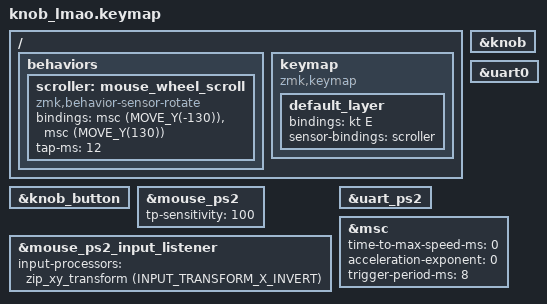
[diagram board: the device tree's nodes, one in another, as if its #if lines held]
#include <behaviors.dtsi>
#include <dt-bindings/zmk/keys.h>
#include <dt-bindings/zmk/pointing.h>
#include <dt-bindings/zmk/mouse.h>
#include <dt-bindings/zmk/input_transform.h>

&knob {
    status = "okay";
};
&knob_button {
    status = "okay";
};

#ifdef MOUSE_PS2_DT_PRESENT
    &mouse_ps2  {
        status = "okay";
    };

    &mouse_ps2_input_listener {
        status = "okay";
    };

    #ifdef MOUSE_PS2_DRIVER_UART
        &uart0 {
            status = "okay";
        };
        &uart_ps2 {
            status = "okay";
        };
    #else
        &gpio_ps2  {
            status = "okay";
        };
    #endif
#endif

&msc {
    time-to-max-speed-ms = <0>;
    acceleration-exponent = <0>;
    trigger-period-ms = <8>;
};

/ {
    behaviors {
        scroller: mouse_wheel_scroll {
            compatible = "zmk,behavior-sensor-rotate";
            #sensor-binding-cells = <0>;
            bindings = <&msc (MOVE_Y(-130))>, <&msc (MOVE_Y(130))>;
            tap-ms = <12>;
        };
    };

    keymap {
        compatible = "zmk,keymap";

        default_layer {
            bindings = <&kt E>;
            sensor-bindings = <&scroller>;
        };
    };
};

#ifdef MOUSE_PS2_DT_PRESENT
    &mouse_ps2_input_listener {
        input-processors = <&zip_xy_transform (INPUT_TRANSFORM_X_INVERT)>;
    };

	&mouse_ps2 {
		tp-sensitivity = <100>;
	};
#endif
